# MM32L3xx register map
Vendor: MindMotion Ltd.; Series: MM32L3; File version: 1.4
CPU: CM3 r1p1, little endian, no MPU, no FPU, 4 interrupt priority bits
Registers are 32-bit, read-write, reset 0x0 unless marked. A register's access mark holds for its fields unless they carry their own. Offsets are from the block's base; [hi:lo] are bit positions; {n}, {i} and the like mark numbered series.

## EXTI
Base 0x40010400
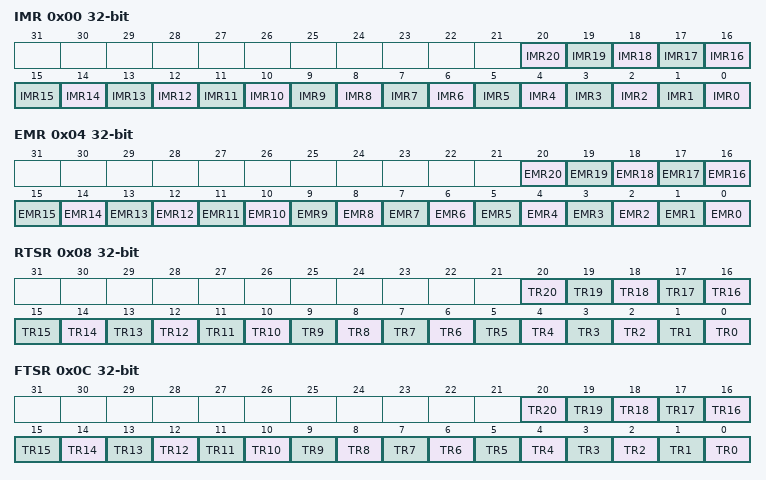
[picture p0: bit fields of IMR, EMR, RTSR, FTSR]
0x00 IMR
  [n] IMR{n} (n=0..20) — Interrupt Mask on line {n}
0x04 EMR
  [n] EMR{n} (n=0..20) — Event Mask on line {n}
0x08 RTSR
  [n] TR{n} (n=0..20) — Rising trigger event configuration bit of line {n}
0x0C FTSR
  [n] TR{n} (n=0..20) — Falling trigger event configuration bit of line {n}
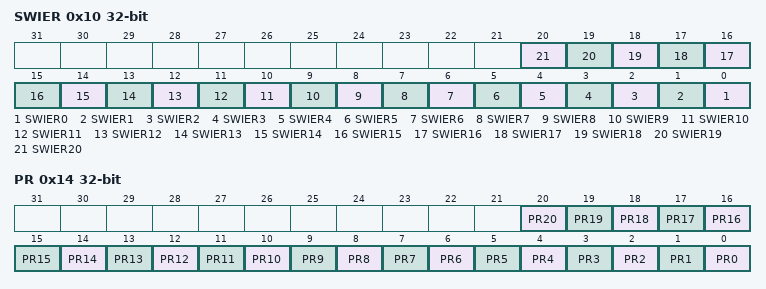
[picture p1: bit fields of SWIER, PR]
0x10 SWIER
  [n] SWIER{n} (n=0..20) — Software interrupt on line {n}
0x14 PR
  [n] PR{n} (n=0..20) — Pending bit

## DMA — DMA controller
Base 0x40020000
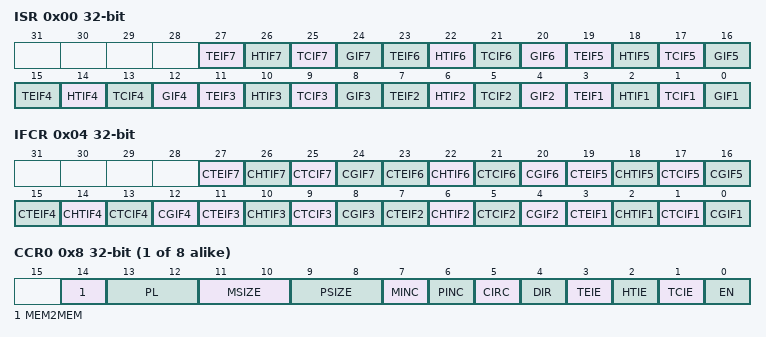
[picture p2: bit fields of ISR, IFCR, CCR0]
0x00 ISR ro
  [4n-1] TEIF{n} (n=1..7) — channel {n} transfer error flag
  [4n-2] HTIF{n} (n=1..7) — channel {n} half transfer flag
  [4n-3] TCIF{n} (n=1..7) — channel {n} half complete flag
  [4n-4] GIF{n} (n=1..7) — channel {n} global interrupt flag
0x04 IFCR ro
  [4n-1] CTEIF{n} (n=1..7) — channel {n} transfer error clear
  [4n-2] CHTIF{n} (n=1..7) — channel {n} half transfer clear
  [4n-3] CTCIF{n} (n=1..7) — channel {n} half complete clear
  [4n-4] CGIF{n} (n=1..7) — channel {n} global interrupt clear
{0x8+0x14*i} CCR{i} (i=0..7)
  [14] MEM2MEM — Memory to memory mode
  [13:12] PL — Channel priority level
  [11:10] MSIZE — Memory size
  [9:8] PSIZE — Peripheral size
  [7] MINC — Memory increment mode
  [6] PINC — Peripheral increment mode
  [5] CIRC — Circular mode
  [4] DIR — Data transfer direction
  [3] TEIE — Transfer error interrupt enable
  [2] HTIE — Half transfer interrupt enable
  [1] TCIE — Transfer complete interrupt enable
  [0] EN — Channel enable
{0xC+0x14*i} CNDTR{i} (i=0..5)
  [15:0] NDT — Number of data to transfer
{0x10+0x14*i} CPAR{i} (i=0..7)
  [31:0] PA — Peripheral address
{0x14+0x14*i} CMAR{i} (i=0..7)
  [31:0] MA — Memory address
0x84 CNDTR6 — DMA_CNDTR6
  [15:0] NDT — Number of data to transfer
0x98 CNDTR7
  [15:0] NDT — Number of data to transfer

## BKP — Backup registers
Base 0x40006C00
{0x0+4i} DR{i} (i=1..3)
  [31:0] D — Backup data
0x10 DR4
  [1:0] D — Backup data
{0x0+4i} DR{i} (i=5..10)
  [31:0] D — Backup data
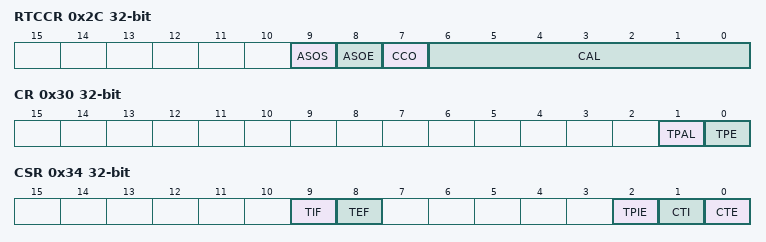
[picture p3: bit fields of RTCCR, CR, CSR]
0x2C RTCCR
  [9] ASOS — Alarm or second output selection
  [8] ASOE — Alarm or second output enable
  [7] CCO — Calibration clock output
  [6:0] CAL — Calibration value
0x30 CR
  [1] TPAL — TAMPER pin active level
  [0] TPE — TAMPER pin enable
0x34 CSR ro
  [9] TIF — Tamper interrupt flag
  [8] TEF — Tamper event flag
  [2] TPIE — TAMPER pin interrupt enable
  [1] CTI — Clear tamper interrupt
  [0] CTE — Clear tamper event

## WWDG — Window watchdog
Base 0x40002C00
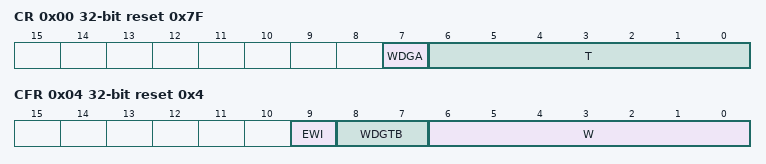
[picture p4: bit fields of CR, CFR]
0x00 CR reset 0x7F
  [7] WDGA — Activation bit
  [6:0] T — 7-bit counter
0x04 CFR reset 0x4
  [9] EWI — Early wakeup interrupt
  [8:7] WDGTB — Timer base
  [6:0] W — 7-bit window value
0x08 SR
  [0] EWIF — Early wakeup interrupt flag

## IWDG — Independent watchdog
Base 0x40003000
0x00 KR wo
  [15:0] KEY — Key value
0x04 PR
  [2:0] PR — Prescaler divider
0x08 RLR
  [11:0] RL — Watchdog counter reload value
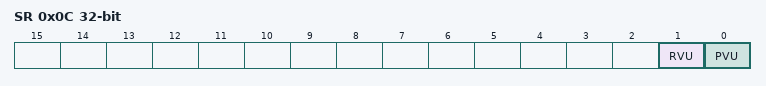
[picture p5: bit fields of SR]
0x0C SR ro
  [1] RVU — Watchdog counter reload value update
  [0] PVU — Watchdog prescaler value update

## RTC — Real time clock
Base 0x40002800
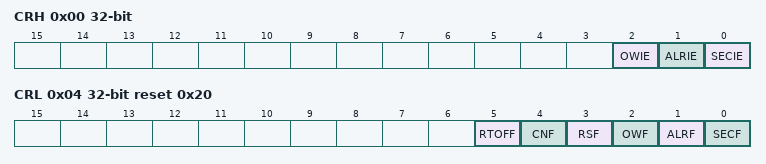
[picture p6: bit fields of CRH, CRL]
0x00 CRH
  [2] OWIE — Overflow interrupt enable
  [1] ALRIE — Alarm interrupt enable
  [0] SECIE — Second interrupt enable
0x04 CRL reset 0x20
  [5] RTOFF — RTC operation OFF
  [4] CNF — Configuration flag
  [3] RSF — Registers synchronized flag
  [2] OWF — Overflow flag
  [1] ALRF — Alarm flag
  [0] SECF — Second flag
0x08 PRLH wo
  [3:0] RTC_PRLH — RTC prescaler reload value high
0x0C PRLL wo
  [15:0] RTC_PRLL — RTC prescaler reload value low
0x10 DIVH ro
  [3:0] RTC_DIVH — RTC clock divider high
0x14 DIVL ro
  [15:0] RTC_DIVL — RTC clock divider low
0x18 CNTH
  [15:0] RTC_CNTH — RTC counter high
0x1C CNTL
  [15:0] RTC_CNTL — RTC counter low
0x20 ALRH wo reset 0xFFFF
  [15:0] RTC_ALRH — RTC alarm high
0x24 ALRL wo reset 0xFFFF
  [15:0] RTC_ALRL — RTC alarm low
